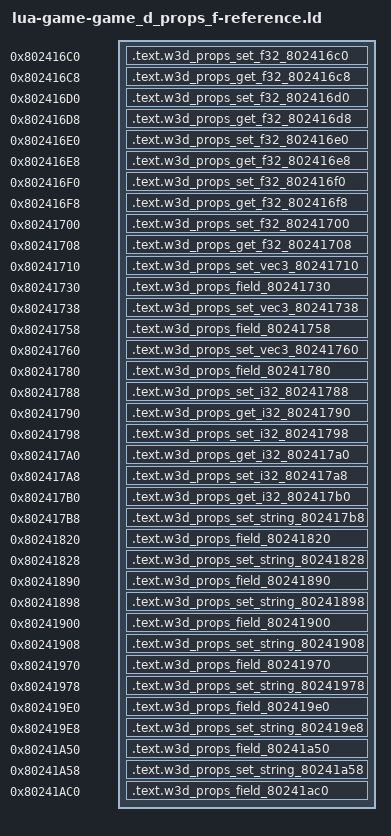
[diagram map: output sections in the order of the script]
/* Generated reference-only placements. All bodies are source-built. */
OUTPUT_FORMAT("elf32-powerpc")
OUTPUT_ARCH(powerpc)
ENTRY(w3d_props_set_f32_802416c0)
_SDA_BASE_ = 0x804b2540;
_SDA2_BASE_ = 0x804c2540;
w3d_string_release_header = 0x8020bb2c;
SECTIONS {
  .text.w3d_props_set_f32_802416c0 0x802416c0 : { *(.text.w3d_props_set_f32_802416c0) }
  .text.w3d_props_get_f32_802416c8 0x802416c8 : { *(.text.w3d_props_get_f32_802416c8) }
  .text.w3d_props_set_f32_802416d0 0x802416d0 : { *(.text.w3d_props_set_f32_802416d0) }
  .text.w3d_props_get_f32_802416d8 0x802416d8 : { *(.text.w3d_props_get_f32_802416d8) }
  .text.w3d_props_set_f32_802416e0 0x802416e0 : { *(.text.w3d_props_set_f32_802416e0) }
  .text.w3d_props_get_f32_802416e8 0x802416e8 : { *(.text.w3d_props_get_f32_802416e8) }
  .text.w3d_props_set_f32_802416f0 0x802416f0 : { *(.text.w3d_props_set_f32_802416f0) }
  .text.w3d_props_get_f32_802416f8 0x802416f8 : { *(.text.w3d_props_get_f32_802416f8) }
  .text.w3d_props_set_f32_80241700 0x80241700 : { *(.text.w3d_props_set_f32_80241700) }
  .text.w3d_props_get_f32_80241708 0x80241708 : { *(.text.w3d_props_get_f32_80241708) }
  .text.w3d_props_set_vec3_80241710 0x80241710 : { *(.text.w3d_props_set_vec3_80241710) }
  .text.w3d_props_field_80241730 0x80241730 : { *(.text.w3d_props_field_80241730) }
  .text.w3d_props_set_vec3_80241738 0x80241738 : { *(.text.w3d_props_set_vec3_80241738) }
  .text.w3d_props_field_80241758 0x80241758 : { *(.text.w3d_props_field_80241758) }
  .text.w3d_props_set_vec3_80241760 0x80241760 : { *(.text.w3d_props_set_vec3_80241760) }
  .text.w3d_props_field_80241780 0x80241780 : { *(.text.w3d_props_field_80241780) }
  .text.w3d_props_set_i32_80241788 0x80241788 : { *(.text.w3d_props_set_i32_80241788) }
  .text.w3d_props_get_i32_80241790 0x80241790 : { *(.text.w3d_props_get_i32_80241790) }
  .text.w3d_props_set_i32_80241798 0x80241798 : { *(.text.w3d_props_set_i32_80241798) }
  .text.w3d_props_get_i32_802417a0 0x802417a0 : { *(.text.w3d_props_get_i32_802417a0) }
  .text.w3d_props_set_i32_802417a8 0x802417a8 : { *(.text.w3d_props_set_i32_802417a8) }
  .text.w3d_props_get_i32_802417b0 0x802417b0 : { *(.text.w3d_props_get_i32_802417b0) }
  .text.w3d_props_set_string_802417b8 0x802417b8 : { *(.text.w3d_props_set_string_802417b8) }
  .text.w3d_props_field_80241820 0x80241820 : { *(.text.w3d_props_field_80241820) }
  .text.w3d_props_set_string_80241828 0x80241828 : { *(.text.w3d_props_set_string_80241828) }
  .text.w3d_props_field_80241890 0x80241890 : { *(.text.w3d_props_field_80241890) }
  .text.w3d_props_set_string_80241898 0x80241898 : { *(.text.w3d_props_set_string_80241898) }
  .text.w3d_props_field_80241900 0x80241900 : { *(.text.w3d_props_field_80241900) }
  .text.w3d_props_set_string_80241908 0x80241908 : { *(.text.w3d_props_set_string_80241908) }
  .text.w3d_props_field_80241970 0x80241970 : { *(.text.w3d_props_field_80241970) }
  .text.w3d_props_set_string_80241978 0x80241978 : { *(.text.w3d_props_set_string_80241978) }
  .text.w3d_props_field_802419e0 0x802419e0 : { *(.text.w3d_props_field_802419e0) }
  .text.w3d_props_set_string_802419e8 0x802419e8 : { *(.text.w3d_props_set_string_802419e8) }
  .text.w3d_props_field_80241a50 0x80241a50 : { *(.text.w3d_props_field_80241a50) }
  .text.w3d_props_set_string_80241a58 0x80241a58 : { *(.text.w3d_props_set_string_80241a58) }
  .text.w3d_props_field_80241ac0 0x80241ac0 : { *(.text.w3d_props_field_80241ac0) }
  /DISCARD/ : { *(.text*) *(.rodata*) *(.data*) *(.bss*) *(.sdata*) *(.sbss*) *(.comment) }
}
